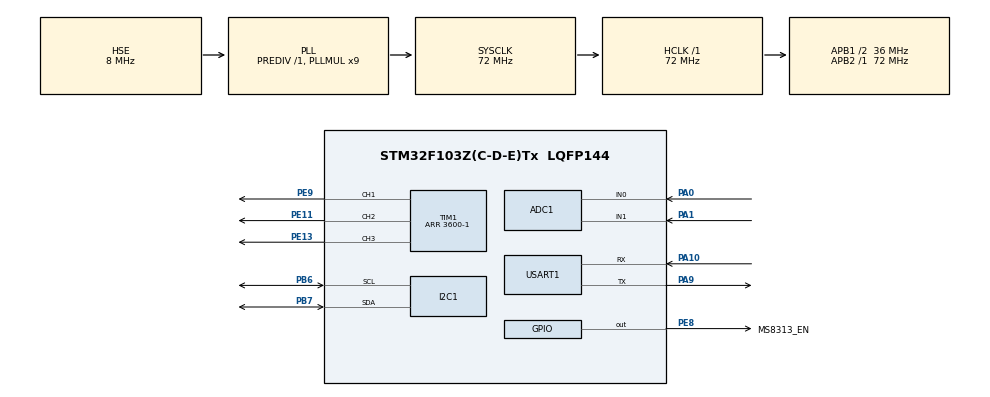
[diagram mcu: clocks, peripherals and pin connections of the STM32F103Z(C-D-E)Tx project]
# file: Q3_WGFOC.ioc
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ADC1.Channel-0\#ChannelRegularConversion=ADC_CHANNEL_0
ADC1.Channel-1\#ChannelRegularConversion=ADC_CHANNEL_1
ADC1.ContinuousConvMode=DISABLE
ADC1.ExternalTrigConv=ADC_EXTERNALTRIGCONV_T1_CC3
ADC1.NbrOfConversion=2
ADC1.NbrOfConversionFlag=1
ADC1.Rank-0\#ChannelRegularConversion=1
ADC1.Rank-1\#ChannelRegularConversion=2
ADC1.SamplingTime-0\#ChannelRegularConversion=ADC_SAMPLETIME_239CYCLES_5
ADC1.SamplingTime-1\#ChannelRegularConversion=ADC_SAMPLETIME_239CYCLES_5
ADC1.master=1
Dma.ADC1.2.Direction=DMA_PERIPH_TO_MEMORY
Dma.ADC1.2.Instance=DMA1_Channel1
Dma.ADC1.2.MemDataAlignment=DMA_MDATAALIGN_HALFWORD
Dma.ADC1.2.MemInc=DMA_MINC_ENABLE
Dma.ADC1.2.Mode=DMA_CIRCULAR
Dma.ADC1.2.PeriphDataAlignment=DMA_PDATAALIGN_HALFWORD
Dma.ADC1.2.PeriphInc=DMA_PINC_DISABLE
Dma.ADC1.2.Priority=DMA_PRIORITY_LOW
Dma.Request0=USART1_RX
Dma.Request1=USART1_TX
Dma.Request2=ADC1
Dma.USART1_RX.0.Direction=DMA_PERIPH_TO_MEMORY
Dma.USART1_RX.0.Instance=DMA1_Channel5
Dma.USART1_RX.0.MemDataAlignment=DMA_MDATAALIGN_BYTE
Dma.USART1_RX.0.MemInc=DMA_MINC_ENABLE
Dma.USART1_RX.0.Mode=DMA_CIRCULAR
Dma.USART1_RX.0.PeriphDataAlignment=DMA_PDATAALIGN_BYTE
Dma.USART1_RX.0.PeriphInc=DMA_PINC_DISABLE
Dma.USART1_RX.0.Priority=DMA_PRIORITY_LOW
Dma.USART1_TX.1.Direction=DMA_MEMORY_TO_PERIPH
Dma.USART1_TX.1.Instance=DMA1_Channel4
Dma.USART1_TX.1.MemDataAlignment=DMA_MDATAALIGN_BYTE
Dma.USART1_TX.1.MemInc=DMA_MINC_ENABLE
Dma.USART1_TX.1.Mode=DMA_NORMAL
Dma.USART1_TX.1.PeriphDataAlignment=DMA_PDATAALIGN_BYTE
Dma.USART1_TX.1.PeriphInc=DMA_PINC_DISABLE
Dma.USART1_TX.1.Priority=DMA_PRIORITY_LOW
Mcu.Family=STM32F1
Mcu.Name=STM32F103Z(C-D-E)Tx
Mcu.Package=LQFP144
NVIC.ADC1_2_IRQn=true\:2\:0\:true\:false\:true\:true\:true\:true
NVIC.DMA1_Channel1_IRQn=true\:0\:0\:false\:false\:true\:false\:true\:true
NVIC.DMA1_Channel4_IRQn=true\:4\:0\:true\:false\:true\:false\:true\:true
NVIC.DMA1_Channel5_IRQn=true\:4\:0\:true\:false\:true\:false\:true\:true
NVIC.I2C1_ER_IRQn=true\:5\:0\:true\:false\:true\:true\:true\:true
NVIC.I2C1_EV_IRQn=true\:5\:0\:true\:false\:true\:true\:true\:true
NVIC.PriorityGroup=NVIC_PRIORITYGROUP_4
NVIC.TIM1_UP_IRQn=true\:1\:0\:true\:false\:true\:true\:true\:true
NVIC.TIM2_IRQn=true\:3\:0\:true\:false\:true\:true\:true\:true
NVIC.USART1_IRQn=true\:4\:0\:true\:false\:true\:true\:true\:true
OSC_IN.Mode=HSE-External-Oscillator
OSC_IN.Signal=RCC_OSC_IN
OSC_OUT.Mode=HSE-External-Oscillator
OSC_OUT.Signal=RCC_OSC_OUT
PA0-WKUP.Signal=ADCx_IN0
PA1.Signal=ADCx_IN1
PA10.Mode=Asynchronous
PA10.Signal=USART1_RX
PA13.Mode=Serial_Wire
PA13.Signal=SYS_JTMS-SWDIO
PA14.Mode=Serial_Wire
PA14.Signal=SYS_JTCK-SWCLK
PA9.Mode=Asynchronous
PA9.Signal=USART1_TX
PB6.Mode=I2C
PB6.Signal=I2C1_SCL
PB7.Mode=I2C
PB7.Signal=I2C1_SDA
PE11.Signal=S_TIM1_CH2
PE13.Signal=S_TIM1_CH3
PE8.GPIO_Label=MS8313_EN
PE8.PinState=GPIO_PIN_SET
PE8.Signal=GPIO_Output
PE9.Signal=S_TIM1_CH1
ProjectManager.HeapSize=0x200
ProjectManager.StackSize=0x400
ProjectManager.TargetToolchain=Makefile
RCC.ADCPresc=RCC_ADCPCLK2_DIV6
RCC.AHBFreq_Value=72000000
RCC.APB1CLKDivider=RCC_HCLK_DIV2
RCC.APB1Freq_Value=36000000
RCC.APB1TimFreq_Value=72000000
RCC.APB2Freq_Value=72000000
RCC.APB2TimFreq_Value=72000000
RCC.HCLKFreq_Value=72000000
RCC.PLLMUL=RCC_PLL_MUL9
RCC.PLLSourceVirtual=RCC_PLLSOURCE_HSE
RCC.SYSCLKFreq_VALUE=72000000
RCC.SYSCLKSource=RCC_SYSCLKSOURCE_PLLCLK
RCC.USBFreq_Value=72000000
SH.ADCx_IN0.0=ADC1_IN0,IN0
SH.ADCx_IN1.0=ADC1_IN1,IN1
SH.S_TIM1_CH1.0=TIM1_CH1,PWM Generation1 CH1
SH.S_TIM1_CH2.0=TIM1_CH2,PWM Generation2 CH2
SH.S_TIM1_CH3.0=TIM1_CH3,PWM Generation3 CH3
TIM1.AutoReloadPreload=TIM_AUTORELOAD_PRELOAD_ENABLE
TIM1.Channel-PWM\ Generation1\ CH1=TIM_CHANNEL_1
TIM1.Channel-PWM\ Generation2\ CH2=TIM_CHANNEL_2
TIM1.Channel-PWM\ Generation3\ CH3=TIM_CHANNEL_3
TIM1.Period=3600-1
TIM1.TIM_MasterOutputTrigger=TIM_TRGO_OC3REF
TIM2.AutoReloadPreload=TIM_AUTORELOAD_PRELOAD_ENABLE
TIM2.Period=1000-1
TIM2.Prescaler=71
USART1.VirtualMode=VM_ASYNC
VP_TIM1_VS_ClockSourceINT.Mode=Internal
VP_TIM2_VS_ClockSourceINT.Mode=Internal
board=custom

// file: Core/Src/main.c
/* USER CODE BEGIN Header */
/**
  ******************************************************************************
  * @file           : main.c
  * @brief          : Main program body
  ******************************************************************************
  * @attention
  *
  * Copyright (c) 2026 STMicroelectronics.
  * All rights reserved.
  *
  * This software is licensed under terms that can be found in the LICENSE file
  * in the root directory of this software component.
  * If no LICENSE file comes with this software, it is provided AS-IS.
  *
  ******************************************************************************
  */
/* USER CODE END Header */
#include "main.h"
#include "adc.h"
#include "dma.h"
#include "i2c.h"
#include "tim.h"
#include "usart.h"
#include "gpio.h"

/* USER CODE BEGIN Includes */
#include "as5600.h"
/* USER CODE END Includes */

void SystemClock_Config(void);

int main(void)
{

  /* MCU Configuration--------------------------------------------------------*/

  /* Reset of all peripherals, Initializes the Flash interface and the Systick. */
  HAL_Init();

  /* Configure the system clock */
  SystemClock_Config();

  /* Initialize all configured peripherals */
  MX_GPIO_Init();
  MX_DMA_Init();
  MX_ADC1_Init();
  MX_I2C1_Init();
  MX_TIM1_Init();
  MX_TIM2_Init();
  MX_USART1_UART_Init();
  /* USER CODE BEGIN 2 */
  HAL_GPIO_WritePin(MS8313_EN_GPIO_Port, MS8313_EN_Pin, GPIO_PIN_SET);  // MS8313 使能

  if (AS5600_Init() != HAL_OK) {
      while (1);  // AS5600 未检测到，停在这里便于调试
  }
  /* USER CODE END 2 */

  /* Infinite loop */
  while (1)
  {

  }
}

void SystemClock_Config(void)
{
  RCC_OscInitTypeDef RCC_OscInitStruct = {0};
  RCC_ClkInitTypeDef RCC_ClkInitStruct = {0};
  RCC_PeriphCLKInitTypeDef PeriphClkInit = {0};

  /** Initializes the RCC Oscillators according to the specified parameters
  * in the RCC_OscInitTypeDef structure.
  */
  RCC_OscInitStruct.OscillatorType = RCC_OSCILLATORTYPE_HSE;
  RCC_OscInitStruct.HSEState = RCC_HSE_ON;
  RCC_OscInitStruct.HSEPredivValue = RCC_HSE_PREDIV_DIV1;
  RCC_OscInitStruct.HSIState = RCC_HSI_ON;
  RCC_OscInitStruct.PLL.PLLState = RCC_PLL_ON;
  RCC_OscInitStruct.PLL.PLLSource = RCC_PLLSOURCE_HSE;
  RCC_OscInitStruct.PLL.PLLMUL = RCC_PLL_MUL9;
  if (HAL_RCC_OscConfig(&RCC_OscInitStruct) != HAL_OK)
  {
    Error_Handler();
  }

  /** Initializes the CPU, AHB and APB buses clocks
  */
  RCC_ClkInitStruct.ClockType = RCC_CLOCKTYPE_HCLK|RCC_CLOCKTYPE_SYSCLK
                              |RCC_CLOCKTYPE_PCLK1|RCC_CLOCKTYPE_PCLK2;
  RCC_ClkInitStruct.SYSCLKSource = RCC_SYSCLKSOURCE_PLLCLK;
  RCC_ClkInitStruct.AHBCLKDivider = RCC_SYSCLK_DIV1;
  RCC_ClkInitStruct.APB1CLKDivider = RCC_HCLK_DIV2;
  RCC_ClkInitStruct.APB2CLKDivider = RCC_HCLK_DIV1;

  if (HAL_RCC_ClockConfig(&RCC_ClkInitStruct, FLASH_LATENCY_2) != HAL_OK)
  {
    Error_Handler();
  }
  PeriphClkInit.PeriphClockSelection = RCC_PERIPHCLK_ADC;
  PeriphClkInit.AdcClockSelection = RCC_ADCPCLK2_DIV6;
  if (HAL_RCCEx_PeriphCLKConfig(&PeriphClkInit) != HAL_OK)
  {
    Error_Handler();
  }
}

void Error_Handler(void)
{
  __disable_irq();
  while (1)
  {
  }
}
